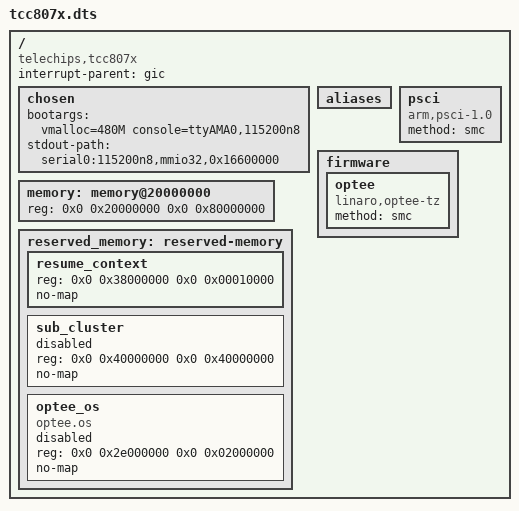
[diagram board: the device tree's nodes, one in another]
// SPDX-License-Identifier: (GPL-2.0-or-later OR MIT)
/*
 * Copyright (C) 2023 Telechips Inc.
 */

/dts-v1/;

/ {
	compatible = "telechips,tcc807x";
	interrupt-parent = <&gic>;
	#address-cells = <2>;
	#size-cells = <2>;

	chosen: chosen {
		bootargs = "vmalloc=480M console=ttyAMA0,115200n8";
		stdout-path = "serial0:115200n8,mmio32,0x16600000";
	};

	aliases: aliases {};

	memory: memory@20000000 {
		device_type = "memory";
		/* updated by U-Boot with actual size */
		reg = <0x0 0x20000000 0x0 0x80000000>;
	};

	psci: psci {
		compatible = "arm,psci-1.0";
		method = "smc";
	};

	reserved_memory: reserved-memory {
		#address-cells = <2>;
		#size-cells = <2>;
		ranges;

		resume_context {
			reg = <0x0 0x38000000 0x0 0x00010000>;
			no-map;
		};

		sub_cluster {
			reg = <0x0 0x40000000 0x0 0x40000000>;
			no-map;
			status = "disabled"; /* enabled by U-Boot if needed */
		};

		optee_os {
			compatible = "optee.os";
			reg = <0x0 0x2e000000 0x0 0x02000000>;
			no-map;
			status = "disabled"; /* enabled by U-Boot if needed */
		};
	};

	firmware {
		optee {
			compatible = "linaro,optee-tz";
			method = "smc";
		};
	};
};

#include "tcc807x-cpu.dtsi"
#include "tcc807x-clk.dtsi"
#include "tcc807x-reboot-mode.dtsi"
#include "tcc807x-reset.dtsi"
#include "tcc807x-mbox.dtsi"
#include "tcc807x-smmu.dtsi"
#include "tcc807x-scfw.dtsi"
#include "tcc807x-gpio.dtsi"
#include "tcc807x-uart.dtsi"
#include "tcc807x-wdt.dtsi"
#include "tcc807x-dma.dtsi"
#include "tcc807x-mmc.dtsi"
#include "tcc807x-i2c.dtsi"
#include "tcc807x-adc.dtsi"
#include "tcc807x-ufs.dtsi"
#include "tcc807x-spi.dtsi"
#include "tcc807x-pic.dtsi"
#include "tcc807x-timer.dtsi"
#include "tcc807x-rtc.dtsi"
#include "tcc807x-thermal.dtsi"
#include "tcc807x-ecid.dtsi"
#include "tcc807x-ipi.dtsi"
#include "tcc807x-pwm.dtsi"
#include "tcc807x-gmac.dtsi"
#include "tcc807x-pcie.dtsi"
#include "tcc807x-usb.dtsi"
#include "tcc807x-ictc.dtsi"
#include "tcc807x-can.dtsi"
#include "tcc807x-hsm.dtsi"
#include "tcc807x-rng.dtsi"
#include "tcc807x-audio.dtsi"
#include "tcc807x-vpu.dtsi"
#include "tcc807x-touchbridge.dtsi"
#include "tcc807x-tccipc.dtsi"
#include "tcc807x-gpu.dtsi"
#include "tcc807x-ethosn.dtsi"
#include "tcc807x-tccvdec.dtsi"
